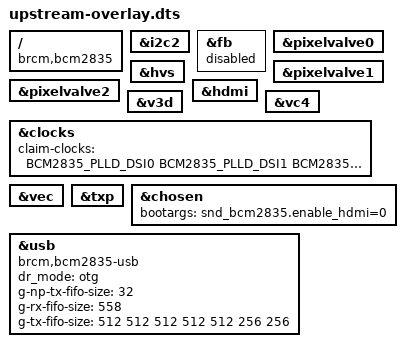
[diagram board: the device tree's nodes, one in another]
// redo: ovmerge -c vc4-kms-v3d-overlay.dts,cma-default,composite dwc2-overlay.dts,dr_mode=otg

/dts-v1/;
/plugin/;

#include <dt-bindings/clock/bcm2835.h>

/ {
	compatible = "brcm,bcm2835";
	fragment@0 {
		target = <&i2c2>;
		__overlay__ {
			status = "okay";
		};
	};
	fragment@1 {
		target = <&fb>;
		__overlay__ {
			status = "disabled";
		};
	};
	fragment@2 {
		target = <&pixelvalve0>;
		__overlay__ {
			status = "okay";
		};
	};
	fragment@3 {
		target = <&pixelvalve1>;
		__overlay__ {
			status = "okay";
		};
	};
	fragment@4 {
		target = <&pixelvalve2>;
		__overlay__ {
			status = "okay";
		};
	};
	fragment@5 {
		target = <&hvs>;
		__overlay__ {
			status = "okay";
		};
	};
	fragment@6 {
		target = <&hdmi>;
		__overlay__ {
			status = "okay";
		};
	};
	fragment@7 {
		target = <&v3d>;
		__overlay__ {
			status = "okay";
		};
	};
	fragment@8 {
		target = <&vc4>;
		__overlay__ {
			status = "okay";
		};
	};
	fragment@9 {
		target = <&clocks>;
		__overlay__ {
			claim-clocks = <BCM2835_PLLD_DSI0 BCM2835_PLLD_DSI1 BCM2835_PLLH_AUX BCM2835_PLLH_PIX>;
		};
	};
	fragment@10 {
		target = <&vec>;
		__overlay__ {
			status = "okay";
		};
	};
	fragment@11 {
		target = <&txp>;
		__overlay__ {
			status = "okay";
		};
	};
	fragment@12 {
		target = <&chosen>;
		__overlay__ {
			bootargs = "snd_bcm2835.enable_hdmi=0";
		};
	};
	fragment@13 {
		target = <&usb>;
		#address-cells = <1>;
		#size-cells = <1>;
		__overlay__ {
			compatible = "brcm,bcm2835-usb";
			dr_mode = "otg";
			g-np-tx-fifo-size = <32>;
			g-rx-fifo-size = <558>;
			g-tx-fifo-size = <512 512 512 512 512 256 256>;
			status = "okay";
		};
	};
};
